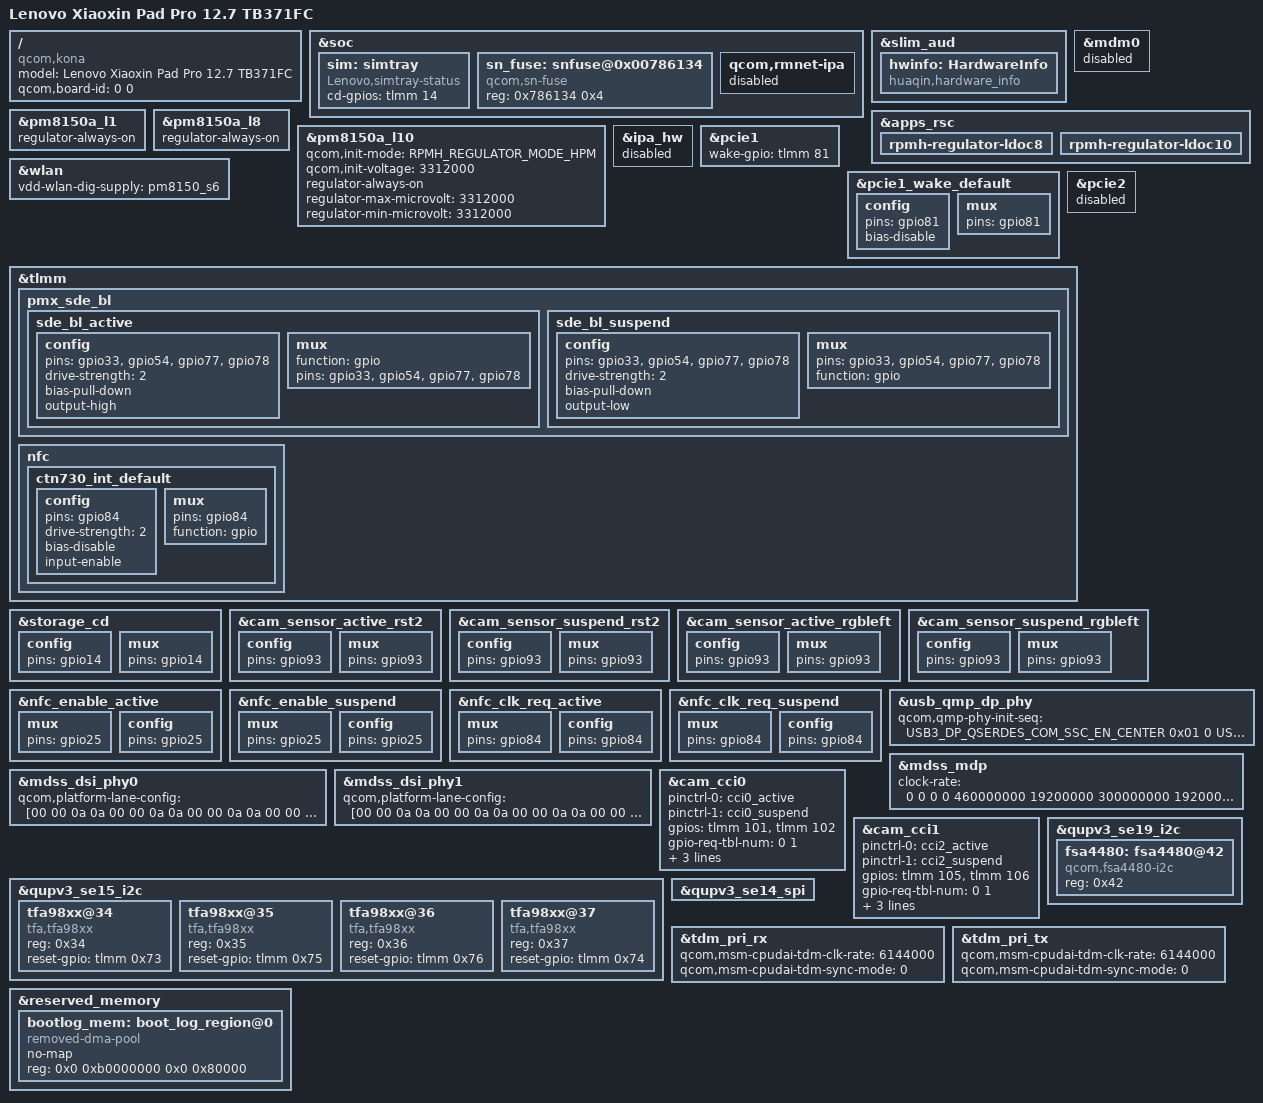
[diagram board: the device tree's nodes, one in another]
/dts-v1/;

#include "kona-v2.1.dtsi"

/ {
	model = "Lenovo Xiaoxin Pad Pro 12.7 TB371FC";
	compatible = "qcom,kona";
	qcom,board-id = <0 0>;
};

&soc {
	sim: simtray {
		compatible = "Lenovo,simtray-status";
		cd-gpios = <&tlmm 14 GPIO_ACTIVE_HIGH>;
	};

	sn_fuse: snfuse@0x00786134 {
		compatible = "qcom,sn-fuse";
		reg = <0x786134 0x4>;
		reg-names = "sn-base";
	};

	qcom,rmnet-ipa {
		status = "disabled";
	};
};

&slim_aud {
	hwinfo: HardwareInfo {
		compatible = "huaqin,hardware_info";
		status = "okay";
	};
};

&mdm0 {
	status = "disabled";
};

&apps_rsc {
	rpmh-regulator-ldoc8 {
		status = "ok";
	};

	rpmh-regulator-ldoc10 {
		status = "ok";
	};
};

&pm8150a_l1 {
	regulator-always-on;
	status = "ok";
};

&pm8150a_l8 {
	regulator-always-on;
	status = "ok";
};

&pm8150a_l10 {
	qcom,init-mode = <RPMH_REGULATOR_MODE_HPM>;
	qcom,init-voltage = <3312000>;
	regulator-always-on;
	regulator-max-microvolt = <3312000>;
	regulator-min-microvolt = <3312000>;
	status = "ok";
};

&ipa_hw {
	status = "disabled";
};

&wlan {
	vdd-wlan-dig-supply = <&pm8150_s6>;
};

&pcie1 {
	wake-gpio = <&tlmm 81 GPIO_ACTIVE_HIGH>;
};

&pcie1_wake_default {
	config {
		/delete-property/ bias-pull-up;
		pins = "gpio81";
		bias-disable;
	};

	mux {
		pins = "gpio81";
	};
};

&pcie2 {
	status = "disabled";
};

&tlmm {
    /*
     * Note:
     *
     * The original tb371fc base DTB does not contain `pmx_sde` node.
     *
     * To keep the inherited `kona-pinctrl.dtsi` untouched,
     * the DTS could use `/delete-node/ pmx_sde;`,
     * but this directive does not apply at runtime during DTBO merging.
     *
     * The overlay may inherit `kona-sde-display.dtsi`,
     * containing the following default assignments:
     *
     *   pinctrl-0 = <&sde_dsi_active &sde_te_active>;
     *   pinctrl-1 = <&sde_dsi_suspend &sde_te_suspend>;
     *
     * ...where `sde_dsi_active` and `sde_dsi_suspend` are defined in `pmx_sde`.
     *
     * Later files or fragments may override these assignments, e.g.:
     *
     *   pinctrl-0 = <&sde_te_active &sde_bl_active>;
     *   pinctrl-1 = <&sde_te_suspend &sde_bl_suspend>;
     *
     * ...which no longer use `sde_dsi_active` and `sde_dsi_suspend`.
     *
     * However, because DTC evaluates all referenced labels when generating
     * the overlay binary, the unused `sde_dsi_*` labels are still compiled
     * into the `__fixups__` table.
     *
     * As a result, the compiled DTBO contains dangling phandle references
     * to labels missing from the base DTB, causing the bootloader's overlay
     * engine to fail during boot.
     *
     * So, instead of deleting the node here,
     * the whole node is commented out from `kona-pinctrl.dtsi`
     */

	// /delete-node/ pmx_sde;

	pmx_sde_bl {
		sde_bl_active: sde_bl_active {
			config {
				pins = "gpio33", "gpio54", "gpio77", "gpio78";
				drive-strength = <2>;   /* 2 mA */
				bias-pull-down;
				output-high;
			};

			mux {
				function = "gpio";
				pins = "gpio33", "gpio54", "gpio77", "gpio78";
			};
		};

		sde_bl_suspend: sde_bl_suspend {
			config {
				pins = "gpio33", "gpio54", "gpio77", "gpio78";
				drive-strength = <2>;   /* 2 mA */
				bias-pull-down;
				output-low;
			};

			mux {
				pins = "gpio33", "gpio54", "gpio77", "gpio78";
				function = "gpio";
			};
		};
	};

	nfc {
		ctn730_int_default: ctn730_int_default {
			config {
				pins = "gpio84";
				drive-strength = <2>;   /* 2 mA */
				bias-disable;
				input-enable;
			};

			mux {
				pins = "gpio84";
				function = "gpio";
			};
		};
	};
};

&storage_cd {
	config {
		pins = "gpio14";
	};

	mux {
		pins = "gpio14";
	};
};

&cam_sensor_active_rst2 {
	config {
		pins = "gpio93";
	};

	mux {
		pins = "gpio93";
	};
};
&cam_sensor_suspend_rst2 {
	config {
		pins = "gpio93";
	};

	mux {
		pins = "gpio93";
	};
};

&cam_sensor_active_rgbleft {
	config {
		pins = "gpio93";
	};

	mux {
		pins = "gpio93";
	};
};

&cam_sensor_suspend_rgbleft {
	config {
		pins = "gpio93";
	};

	mux {
		pins = "gpio93";
	};
};

&nfc_enable_active {
	mux {
		pins = "gpio25";
	};

	config {
		pins = "gpio25";
	};
};

&nfc_enable_suspend {
	mux {
		pins = "gpio25";
	};

	config {
		pins = "gpio25";
	};
};

&nfc_clk_req_active {
	mux {
		pins = "gpio84";
	};

	config {
		pins = "gpio84";
	};
};

&nfc_clk_req_suspend {
	mux {
		pins = "gpio84";
	};

	config {
		pins = "gpio84";
	};
};


&usb_qmp_dp_phy {
	qcom,qmp-phy-init-seq = /* <reg_offset, value, delay> */
				<USB3_DP_QSERDES_COM_SSC_EN_CENTER 0x01 0
				 USB3_DP_QSERDES_COM_SSC_PER1 0x31 0
				 USB3_DP_QSERDES_COM_SSC_PER2 0x01 0
				 USB3_DP_QSERDES_COM_SSC_STEP_SIZE1_MODE0 0xDE 0
				 USB3_DP_QSERDES_COM_SSC_STEP_SIZE2_MODE0 0x07 0
				 USB3_DP_QSERDES_COM_SSC_STEP_SIZE1_MODE1 0xDE 0
				 USB3_DP_QSERDES_COM_SSC_STEP_SIZE2_MODE1 0x07 0
				 USB3_DP_QSERDES_COM_SYSCLK_BUF_ENABLE 0x0A 0
				 USB3_DP_QSERDES_COM_CMN_IPTRIM 0x20 0
				 USB3_DP_QSERDES_COM_CP_CTRL_MODE0 0x06 0
				 USB3_DP_QSERDES_COM_CP_CTRL_MODE1 0x06 0
				 USB3_DP_QSERDES_COM_PLL_RCTRL_MODE0 0x16 0
				 USB3_DP_QSERDES_COM_PLL_RCTRL_MODE1 0x16 0
				 USB3_DP_QSERDES_COM_PLL_CCTRL_MODE0 0x36 0
				 USB3_DP_QSERDES_COM_PLL_CCTRL_MODE1 0x36 0
				 USB3_DP_QSERDES_COM_SYSCLK_EN_SEL 0x1A 0
				 USB3_DP_QSERDES_COM_LOCK_CMP_EN 0x04 0
				 USB3_DP_QSERDES_COM_LOCK_CMP1_MODE0 0x14 0
				 USB3_DP_QSERDES_COM_LOCK_CMP2_MODE0 0x34 0
				 USB3_DP_QSERDES_COM_LOCK_CMP1_MODE1 0x34 0
				 USB3_DP_QSERDES_COM_LOCK_CMP2_MODE1 0x82 0
				 USB3_DP_QSERDES_COM_DEC_START_MODE0 0x82 0
				 USB3_DP_QSERDES_COM_DEC_START_MODE1 0x82 0
				 USB3_DP_QSERDES_COM_DIV_FRAC_START1_MODE0 0xAB 0
				 USB3_DP_QSERDES_COM_DIV_FRAC_START2_MODE0 0xEA 0
				 USB3_DP_QSERDES_COM_DIV_FRAC_START3_MODE0 0x02 0
				 USB3_DP_QSERDES_COM_DIV_FRAC_START1_MODE1 0xAB 0
				 USB3_DP_QSERDES_COM_DIV_FRAC_START2_MODE1 0xEA 0
				 USB3_DP_QSERDES_COM_DIV_FRAC_START3_MODE1 0x02 0
				 USB3_DP_QSERDES_COM_VCO_TUNE_MAP 0x02 0
				 USB3_DP_QSERDES_COM_VCO_TUNE1_MODE0 0x24 0
				 USB3_DP_QSERDES_COM_VCO_TUNE1_MODE1 0x24 0
				 USB3_DP_QSERDES_COM_VCO_TUNE2_MODE1 0x02 0
				 USB3_DP_QSERDES_COM_HSCLK_SEL 0x01 0
				 USB3_DP_QSERDES_COM_CORECLK_DIV_MODE1 0x08 0
				 USB3_DP_QSERDES_COM_BIN_VCOCAL_CMP_CODE1_MODE0 0xCA 0
				 USB3_DP_QSERDES_COM_BIN_VCOCAL_CMP_CODE2_MODE0 0x1E 0
				 USB3_DP_QSERDES_COM_BIN_VCOCAL_CMP_CODE1_MODE1 0xCA 0
				 USB3_DP_QSERDES_COM_BIN_VCOCAL_CMP_CODE2_MODE1 0x1E 0
				 USB3_DP_QSERDES_COM_BIN_VCOCAL_HSCLK_SEL 0x11 0
				 USB3_DP_QSERDES_TXA_RES_CODE_LANE_TX 0x60 0
				 USB3_DP_QSERDES_TXA_RES_CODE_LANE_RX 0x60 0
				 USB3_DP_QSERDES_TXA_RES_CODE_LANE_OFFSET_TX 0x11 0
				 USB3_DP_QSERDES_TXA_RES_CODE_LANE_OFFSET_RX 0x02 0
				 USB3_DP_QSERDES_TXA_TX_DRV_LVL 0x3f 0x0  /* added */
				 USB3_DP_QSERDES_TXA_TX_EMP_POST1_LVL 0x37 0x0  /* added */
				 USB3_DP_QSERDES_TXA_LANE_MODE_1 0xD5 0
				 USB3_DP_QSERDES_TXA_LANE_MODE_2 0x00 0
				 USB3_DP_QSERDES_TXA_RCV_DETECT_LVL_2 0x12 0
				 USB3_DP_QSERDES_TXA_PI_QEC_CTRL 0x40 0
				 USB3_DP_QSERDES_RXA_UCDR_FO_GAIN 0x09 0
				 USB3_DP_QSERDES_RXA_UCDR_SO_GAIN 0x05 0
				 USB3_DP_QSERDES_RXA_UCDR_FASTLOCK_FO_GAIN 0x2F 0
				 USB3_DP_QSERDES_RXA_UCDR_SO_SATURATION_AND_ENABLE 0x7F 0
				 USB3_DP_QSERDES_RXA_UCDR_FASTLOCK_COUNT_LOW 0xFF 0
				 USB3_DP_QSERDES_RXA_UCDR_FASTLOCK_COUNT_HIGH 0x0F 0
				 USB3_DP_QSERDES_RXA_UCDR_PI_CONTROLS 0x99 0
				 USB3_DP_QSERDES_RXA_UCDR_SB2_THRESH1 0x08 0
				 USB3_DP_QSERDES_RXA_UCDR_SB2_THRESH2 0x08 0
				 USB3_DP_QSERDES_RXA_UCDR_SB2_GAIN1 0x00 0
				 USB3_DP_QSERDES_RXA_UCDR_SB2_GAIN2 0x04 0
				 USB3_DP_QSERDES_RXA_VGA_CAL_CNTRL1 0x54 0
				 USB3_DP_QSERDES_RXA_VGA_CAL_CNTRL2 0x0C 0
				 USB3_DP_QSERDES_RXA_RX_EQU_ADAPTOR_CNTRL2 0x0F 0
				 USB3_DP_QSERDES_RXA_RX_EQU_ADAPTOR_CNTRL3 0x4A 0
				 USB3_DP_QSERDES_RXA_RX_EQU_ADAPTOR_CNTRL4 0x0A 0
				 USB3_DP_QSERDES_RXA_RX_IDAC_TSETTLE_LOW 0xC0 0
				 USB3_DP_QSERDES_RXA_RX_IDAC_TSETTLE_HIGH 0x00 0
				 USB3_DP_QSERDES_RXA_RX_EQ_OFFSET_ADAPTOR_CNTRL1 0x77 0
				 USB3_DP_QSERDES_RXA_SIGDET_CNTRL 0x04 0
				 USB3_DP_QSERDES_RXA_SIGDET_DEGLITCH_CNTRL 0x0E 0
				 USB3_DP_QSERDES_RXA_RX_MODE_00_LOW 0xFF 0
				 USB3_DP_QSERDES_RXA_RX_MODE_00_HIGH 0x7F 0
				 USB3_DP_QSERDES_RXA_RX_MODE_00_HIGH2 0x7F 0
				 USB3_DP_QSERDES_RXA_RX_MODE_00_HIGH3 0x7F 0
				 USB3_DP_QSERDES_RXA_RX_MODE_00_HIGH4 0x97 0
				 USB3_DP_QSERDES_RXA_RX_MODE_01_LOW 0xDC 0
				 USB3_DP_QSERDES_RXA_RX_MODE_01_HIGH 0xDC 0
				 USB3_DP_QSERDES_RXA_RX_MODE_01_HIGH2 0x5C 0
				 USB3_DP_QSERDES_RXA_RX_MODE_01_HIGH3 0x7B 0
				 USB3_DP_QSERDES_RXA_RX_MODE_01_HIGH4 0xB4 0
				 USB3_DP_QSERDES_RXA_DFE_EN_TIMER 0x04 0
				 USB3_DP_QSERDES_RXA_DFE_CTLE_POST_CAL_OFFSET 0x38 0
				 USB3_DP_QSERDES_RXA_AUX_DATA_TCOARSE_TFINE 0xA0 0
				 USB3_DP_QSERDES_RXA_DCC_CTRL1 0x0C 0
				 USB3_DP_QSERDES_RXA_GM_CAL 0x1F 0
				 USB3_DP_QSERDES_RXA_VTH_CODE 0x10 0
				 USB3_DP_QSERDES_TXB_RES_CODE_LANE_TX 0x60 0
				 USB3_DP_QSERDES_TXB_RES_CODE_LANE_RX 0x60 0
				 USB3_DP_QSERDES_TXB_RES_CODE_LANE_OFFSET_TX 0x11 0
				 USB3_DP_QSERDES_TXB_RES_CODE_LANE_OFFSET_RX 0x02 0
				 USB3_DP_QSERDES_TXB_TX_DRV_LVL 0x3f 0x0 /* added */
				 USB3_DP_QSERDES_TXB_TX_EMP_POST1_LVL 0x37 0x0 /* added */
				 USB3_DP_QSERDES_TXB_LANE_MODE_1 0xD5 0
				 USB3_DP_QSERDES_TXB_LANE_MODE_2 0x00 0
				 USB3_DP_QSERDES_TXB_RCV_DETECT_LVL_2 0x12 0
				 USB3_DP_QSERDES_TXB_PI_QEC_CTRL 0x54 0
				 USB3_DP_QSERDES_RXB_UCDR_FO_GAIN 0x09 0
				 USB3_DP_QSERDES_RXB_UCDR_SO_GAIN 0x05 0
				 USB3_DP_QSERDES_RXB_UCDR_FASTLOCK_FO_GAIN 0x2F 0
				 USB3_DP_QSERDES_RXB_UCDR_SO_SATURATION_AND_ENABLE 0x7F 0
				 USB3_DP_QSERDES_RXB_UCDR_FASTLOCK_COUNT_LOW 0xFF 0
				 USB3_DP_QSERDES_RXB_UCDR_FASTLOCK_COUNT_HIGH 0x0F 0
				 USB3_DP_QSERDES_RXB_UCDR_PI_CONTROLS 0x99 0
				 USB3_DP_QSERDES_RXB_UCDR_SB2_THRESH1 0x08 0
				 USB3_DP_QSERDES_RXB_UCDR_SB2_THRESH2 0x08 0
				 USB3_DP_QSERDES_RXB_UCDR_SB2_GAIN1 0x00 0
				 USB3_DP_QSERDES_RXB_UCDR_SB2_GAIN2 0x04 0
				 USB3_DP_QSERDES_RXB_VGA_CAL_CNTRL1 0x54 0
				 USB3_DP_QSERDES_RXB_VGA_CAL_CNTRL2 0x0C 0
				 USB3_DP_QSERDES_RXB_RX_EQU_ADAPTOR_CNTRL2 0x0F 0
				 USB3_DP_QSERDES_RXB_RX_EQU_ADAPTOR_CNTRL3 0x4A 0
				 USB3_DP_QSERDES_RXB_RX_EQU_ADAPTOR_CNTRL4 0x0A 0
				 USB3_DP_QSERDES_RXB_RX_IDAC_TSETTLE_LOW 0xC0 0
				 USB3_DP_QSERDES_RXB_RX_IDAC_TSETTLE_HIGH 0x00 0
				 USB3_DP_QSERDES_RXB_RX_EQ_OFFSET_ADAPTOR_CNTRL1 0x77 0
				 USB3_DP_QSERDES_RXB_SIGDET_CNTRL 0x04 0
				 USB3_DP_QSERDES_RXB_SIGDET_DEGLITCH_CNTRL 0x0E 0
				 USB3_DP_QSERDES_RXB_RX_MODE_00_LOW 0x7F 0
				 USB3_DP_QSERDES_RXB_RX_MODE_00_HIGH 0xFF 0
				 USB3_DP_QSERDES_RXB_RX_MODE_00_HIGH2 0x3F 0
				 USB3_DP_QSERDES_RXB_RX_MODE_00_HIGH3 0x7F 0
				 USB3_DP_QSERDES_RXB_RX_MODE_00_HIGH4 0xA6 0
				 USB3_DP_QSERDES_RXB_RX_MODE_01_LOW 0xDC 0
				 USB3_DP_QSERDES_RXB_RX_MODE_01_HIGH 0xDC 0
				 USB3_DP_QSERDES_RXB_RX_MODE_01_HIGH2 0x5C 0
				 USB3_DP_QSERDES_RXB_RX_MODE_01_HIGH3 0x7B 0
				 USB3_DP_QSERDES_RXB_RX_MODE_01_HIGH4 0xB4 0
				 USB3_DP_QSERDES_RXB_DFE_EN_TIMER 0x04 0
				 USB3_DP_QSERDES_RXB_DFE_CTLE_POST_CAL_OFFSET 0x38 0
				 USB3_DP_QSERDES_RXB_AUX_DATA_TCOARSE_TFINE 0xA0 0
				 USB3_DP_QSERDES_RXB_DCC_CTRL1 0x0C 0
				 USB3_DP_QSERDES_RXB_GM_CAL 0x1F 0
				 USB3_DP_QSERDES_RXB_VTH_CODE 0x10 0
				 USB3_DP_PCS_LOCK_DETECT_CONFIG1 0xD0 0
				 USB3_DP_PCS_LOCK_DETECT_CONFIG2 0x07 0
				 USB3_DP_PCS_LOCK_DETECT_CONFIG3 0x20 0
				 USB3_DP_PCS_LOCK_DETECT_CONFIG6 0x13 0
				 USB3_DP_PCS_REFGEN_REQ_CONFIG1 0x21 0
				 USB3_DP_PCS_RX_SIGDET_LVL 0xA9 0
				 USB3_DP_PCS_CDR_RESET_TIME 0x0A 0
				 USB3_DP_PCS_ALIGN_DETECT_CONFIG1 0x88 0
				 USB3_DP_PCS_ALIGN_DETECT_CONFIG2 0x13 0
				 USB3_DP_PCS_PCS_TX_RX_CONFIG 0x0C 0
				 USB3_DP_PCS_EQ_CONFIG1 0x4B 0
				 USB3_DP_PCS_EQ_CONFIG5 0x10 0
				 USB3_DP_PCS_USB3_LFPS_DET_HIGH_COUNT_VAL 0xF8 0
				 USB3_DP_PCS_USB3_RXEQTRAINING_DFE_TIME_S2 0x07 0
				 0xffffffff 0xffffffff 0x00>;
};

&mdss_mdp {
	clock-rate = <0 0 0 0 460000000 19200000 300000000 19200000>;
};

&mdss_dsi_phy0 {
	qcom,platform-lane-config = [00 00 0a 0a
				     00 00 0a 0a
				     00 00 0a 0a
				     00 00 0a 0a
				     20 00 8a 8a];
};

&mdss_dsi_phy1 {
	qcom,platform-lane-config = [00 00 0a 0a
				     00 00 0a 0a
				     00 00 0a 0a
				     00 00 0a 0a
				     20 00 8a 8a];
};

&cam_cci0 {
	pinctrl-0 = <&cci0_active>;
	pinctrl-1 = <&cci0_suspend>;
	gpios = <&tlmm 101 GPIO_ACTIVE_HIGH>,
		<&tlmm 102 GPIO_ACTIVE_HIGH>;
	gpio-req-tbl-num = <0 1>;
	gpio-req-tbl-flags = <1 1>;
	gpio-req-tbl-label = "CCI_I2C_DATA0", "CCI_I2C_CLK0";
};

&cam_cci1 {
	pinctrl-0 = <&cci2_active>;
	pinctrl-1 = <&cci2_suspend>;
	gpios = <&tlmm 105 GPIO_ACTIVE_HIGH>,
		<&tlmm 106 GPIO_ACTIVE_HIGH>;
	gpio-req-tbl-num = <0 1>;
	gpio-req-tbl-flags = <1 1>;
	gpio-req-tbl-label = "CCI_I2C_DATA2", "CCI_I2C_CLK2";
};

&qupv3_se15_i2c {
	status = "ok";

	/delete-node/ fsa4480@43;

	tfa98xx@34 {
		compatible = "tfa,tfa98xx";
		reg = <0x34>;
		reset-gpio = <&tlmm 0x73 GPIO_ACTIVE_HIGH>;
	};

	tfa98xx@35 {
		compatible = "tfa,tfa98xx";
		reg = <0x35>;
		reset-gpio = <&tlmm 0x75 GPIO_ACTIVE_HIGH>;
	};

	tfa98xx@36 {
		compatible = "tfa,tfa98xx";
		reg = <0x36>;
		reset-gpio = <&tlmm 0x76 GPIO_ACTIVE_HIGH>;
	};

	tfa98xx@37 {
		compatible = "tfa,tfa98xx";
		reg = <0x37>;
		reset-gpio = <&tlmm 0x74 GPIO_ACTIVE_HIGH>;
	};
};

&qupv3_se19_i2c {
	status = "ok";

	fsa4480: fsa4480@42 {
		compatible = "qcom,fsa4480-i2c";
		reg = <0x42>;
	};
};

&qupv3_se14_spi {
	status = "ok";
};

&tdm_pri_rx {
	qcom,msm-cpudai-tdm-clk-rate = <6144000>;
	qcom,msm-cpudai-tdm-sync-mode = <0>;
};

&tdm_pri_tx {
	qcom,msm-cpudai-tdm-clk-rate = <6144000>;
	qcom,msm-cpudai-tdm-sync-mode = <0>;
};

&reserved_memory {
	bootlog_mem: boot_log_region@0 {
		compatible = "removed-dma-pool";
		no-map;
		reg = <0x0 0xb0000000 0x0 0x80000>;
	};
};
